# CTRL_MMR0_CFG0 register map
Vendor: Texas Instruments
Registers are 32-bit, read-write, reset 0x0 unless marked. A register's access mark holds for its fields unless they carry their own. Offsets are as the file gives them; [hi:lo] are bit positions; {n}, {i} and the like mark numbered series.

## CTRL_MMR0_CFG0 (part 9 of 10)
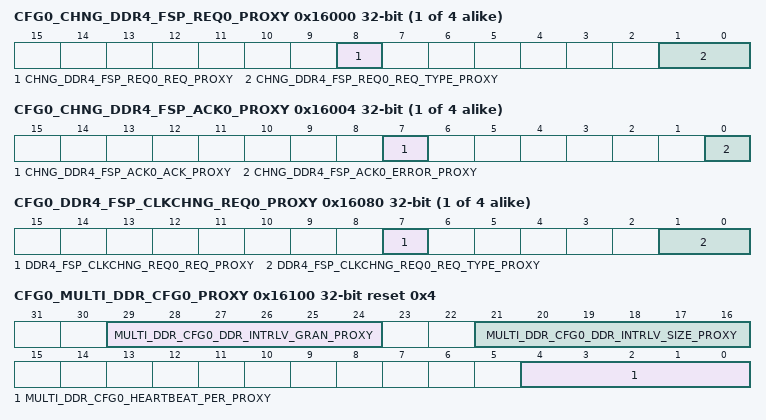
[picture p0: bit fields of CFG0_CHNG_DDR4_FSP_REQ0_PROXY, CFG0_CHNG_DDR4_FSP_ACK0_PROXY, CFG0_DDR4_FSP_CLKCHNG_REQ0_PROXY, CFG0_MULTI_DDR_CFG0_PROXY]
{0x16000+0x10*i} CFG0_CHNG_DDR4_FSP_REQ{i}_PROXY (i=0..3) — This register is used to initiate a LPDDR4 frequency set point change to the DDR {i} Controller
  [8] CHNG_DDR4_FSP_REQ{i}_REQ_PROXY — Initiate FSP frequency change
  [1:0] CHNG_DDR4_FSP_REQ{i}_REQ_TYPE_PROXY — Frequency request typeIndicates which DDR4 frequency set point to change to
{0x16004+0x10*i} CFG0_CHNG_DDR4_FSP_ACK{i}_PROXY ro (i=0..3) — This register is used by the DDR {i} Controller to acknowledge the LPDDR4 frequency set point change request
  [7] CHNG_DDR4_FSP_ACK{i}_ACK_PROXY — Frequency change acknowledge.This bit is only valid when CHNG_DDR4_FSP_REQ_req = 1Indication from the DDR Controller that the FSP change operation is complete 0 - FSP change operation in progress 1 - FSP change operation complete
  [0] CHNG_DDR4_FSP_ACK{i}_ERROR_PROXY — Frequency change errorThis bit is only valid when CHNG_DDR4_FSP_REQ_req = 1 0 - FSP change was successful 1 - FSP change was not successful
{0x16080+0x10*i} CFG0_DDR4_FSP_CLKCHNG_REQ{i}_PROXY ro (i=0..3) — This register is used by the DDR {i} Controller to request the DDR{i} PLL clock frequency change. This can occur as part of DDR4 initialization and training or in response to a LPDDR4 FSP change request.
  [7] DDR4_FSP_CLKCHNG_REQ{i}_REQ_PROXY — DDR Controller FSP clock change requestIndicates that the DDR controller needs the DDR clock changed to the frequency indicated by the req_type field. This bit is cleared when the DDR4_FSP_CLKCHNG_ACK_ack bit is set.
  [1:0] DDR4_FSP_CLKCHNG_REQ{i}_REQ_TYPE_PROXY — Frequency request typeIndicates which DDR4 FSP frequency to which the DDR Controller wants the DDR clock set
{0x160C0+0x10*i} CFG0_DDR4_FSP_CLKCHNG_ACK{i}_PROXY (i=0..3) — This register is used to acknowledge a DDR{i} PLL clock frequency change to the DDR{i} Controller.
  [0] DDR4_FSP_CLKCHNG_ACK{i}_ACK_PROXY — DDR FSP clock change acknowledgeThis bit should be set once the DDR clock has been successfully changed to the value requested by DDR4_FSP_CLKCHNG_REQ_req_type. Setting this bit will clear the DDR4_FSP_CLKCHNG_REQ_req bit and the associated change request interrupt.
0x16100 CFG0_MULTI_DDR_CFG0_PROXY reset 0x4 — Configures DDR interleaving
  [29:24] MULTI_DDR_CFG0_DDR_INTRLV_GRAN_PROXY — Defines the size of each memory stripe for interleaved memory space. Value takes effect when MULTI_DDR_CFG1_ddr_cfg _load field is set as 4'b0110. Field values (Others are reserved): 6'b000000 - 128 B 6'b000001 - 512 B 6'b000010 - 2 KB 6'b000011 - 4 KB 6'b000100 - 16 KB 6'b000101 - 32 KB 6'b000110 - 512 MB 6'b000111 - 1 GB 6'b001000 - 1.5 GB 6'b001001 - 2 GB 6'b001010 - 3 GB 6'b001011 - 4 GB 6'b001100 - 6 GB 6'b001101 - 8 GB 6'b001110 - 16 GB
  [21:16] MULTI_DDR_CFG0_DDR_INTRLV_SIZE_PROXY — Defines the memory window size for the interleaved region starting at the bottom of the external memory address range. Value takes effect when MULTI_DDR_CFG1_ddr_cfg _load field is set as 4'b0110. Field values (Others are reserved): 6'b000000 - 0 (no interleave) 6'b000001 - 128 MB 6'b000010 - 256 MB 6'b000011 - 512 MB 6'b000100 - 1 GB 6'b000101 - 2 GB 6'b000110 - 3 GB 6'b000111 - 4 GB 6'b001000 - 6 GB 6'b001001 - 8 GB 6'b001010 - 12 GB 6'b001011 - 16 GB 6'b001100 - 32 GB
  [4:0] MULTI_DDR_CFG0_HEARTBEAT_PER_PROXY — Determines number of cycles of unsuccessful EMIF arbitration to wait before arbitrating for a different EMIF port. Value takes effect when MULTI_DDR_CFG1_ddr_cfg _load field is set as 4'b0110. 0 - Heartbeat is disabled 1-31 - Number of cycles before port switch
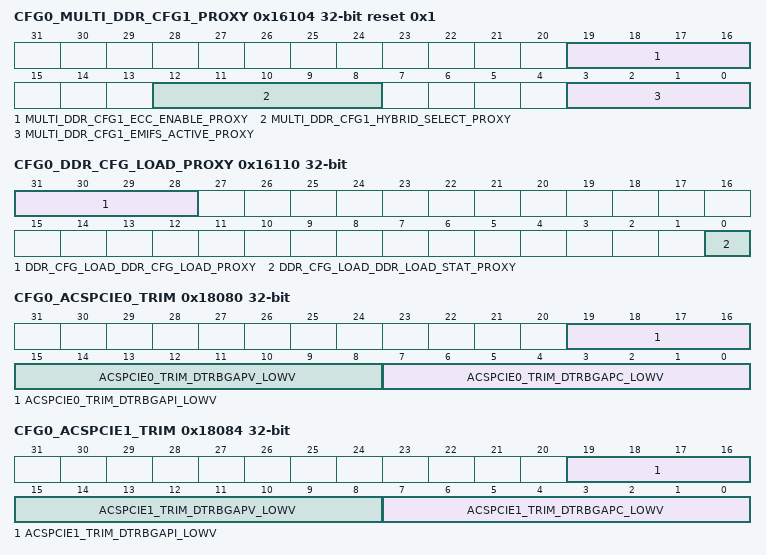
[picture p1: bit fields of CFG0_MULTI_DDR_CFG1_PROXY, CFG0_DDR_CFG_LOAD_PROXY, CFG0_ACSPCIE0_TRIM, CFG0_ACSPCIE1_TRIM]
0x16104 CFG0_MULTI_DDR_CFG1_PROXY reset 0x1 — Configures DDR interleaving
  [19:16] MULTI_DDR_CFG1_ECC_ENABLE_PROXY — Determines which EMIFs have ECC enabled. Value takes effect when MULTI_DDR_CFG1_ddr_cfg _load field is set as 4'b0110. Field values (Others are reserved): 4'b0000 - ECC disabled on all EMIFs 4'b0001 - ECC enabled on EMIF 0 4'b0010 - ECC enabled on EMIF 1 4'b0011 - ECC enabled on EMIF 0,1 4'b0100 - ECC enabled on EMIF 2 4'b0101 - ECC enabled on EMIF 0,2 4'b0110 - ECC enabled on EMIF 1,2 4'b0111 - ECC enabled on EMIF 0,1,2 4'b1000 - ECC enabled on EMIF 3 4'b1001 - ECC enabled on EMIF 0,3 4'b1010 - ECC enabled on EMIF 1,3 4'b1011 - ECC enabled on EMIF 0,1,3 4'b1100 - ECC enabled on EMIF 2,3 4'b1101 - ECC enabled on EMIF 0,2,3 4'b1110 - ECC enabled on EMIF 1,2,3 4'b1111 - ECC enabled on EMIF 0,1,2,3
  [12:8] MULTI_DDR_CFG1_HYBRID_SELECT_PROXY — Determines interleaved EMIF space location. Usage is based on number of EMIFs present. Value takes effect when MULTI_DDR_CFG1_ddr_cfg _load field is set as 4'b0110. Field values (Others are reserved): 4'b00000 - Entire EMIF space is interleaved 4'b00001 - 2 EMIFs - EMIF 0 separated, EMIF 0,1 interleaved 4'b00001 - 3 EMIFs - EMIF 0 separated, EMIF 1,2 interleaved 4'b00001 - 4 EMIFs - EMIF 0 separated, EMIF 1,2,3 interleaved 4'b00010 - 2 EMIFs - EMIF 1 separated, EMIF 0,1 interleaved 4'b00010 - 3 EMIFs - EMIF 1 separated, EMIF 0,2 interleaved 4'b00010 - 4 EMIFs - EMIF 1 separated, EMIF 0,2,3 interleaved 4'b00100 - 2 EMIFS - reserved 4'b00100 - 3 EMIFs - EMIF 2 separated, EMIF 0,1 interleaved 4'b00100 - 4 EMIFs - EMIF 2 separated, EMIF 0,1,3 interleaved 4'b01000 - 2 EMIFS - reserved 4'b01000 - 3 EMIFS - reserved 4'b01000 - 4 EMIFs - EMIF 3 separated, EMIF 0,1,2 interleaved 4'b10000 - reserved 4'b10001 - 2 EMIFs - EMIF 0 separated, EMIF 0,1 interleaved 4'b10001 - 3 EMIFs - EMIF 0 separated, EMIF 0,1,2 interleaved 4'b10001 - 4 EMIFs - EMIF 0 separated, EMIF 0,1,2,3 interleaved 4'b10010 - 2 EMIFs - EMIF 1 separated, EMIF 0,1 interleaved 4'b10010 - 3 EMIFs - EMIF 1 separated, EMIF 0,1,2 interleaved 4'b10010 - 4 EMIFs - EMIF 1 separated, EMIF 0,1,2,3 interleaved 4'b10100 - 2 EMIFS - reserved 4'b10100 - 3 EMIFs - EMIF 2 separated, EMIF 0,1,2 interleaved 4'b10100 - 4 EMIFS - EMIF 2 separated, EMIF 0,1,2,3 interleaved 4'b11000 - 2 EMIFS - reserved 4'b11000 - 3 EMIFS - reserved 4'b11000 - 4 EMIFs - EMIF 3 separated, EMIF 0,1,2,3 interleaved
  [3:0] MULTI_DDR_CFG1_EMIFS_ACTIVE_PROXY — Indicates which EMIF (DDR) interfaces are active. Value takes effect when MULTI_DDR_CFG1_ddr_cfg _load field is set as 4'b0110. Field values (Others are reserved): 4'b0000 - Reserved 4'b0001 - EMIF 0 Active 4'b0010 - EMIF 1 Active 4'b0011 - EMIF 0,1 Active 4'b0100 - EMIF 2 Active 4'b0101 - EMIF 0,2 Active 4'b0110 - EMIF 1,2 Active 4'b0111 - EMIF 0,1,2 Active 4'b1000 - EMIF 3 Active 4'b1001 - EMIF 0,3 Active 4'b1010 - EMIF 1,3 Active 4'b1011 - EMIF 0,1,3 Active 4'b1100 - EMIF 2,3 Active 4'b1101 - EMIF 0,2,3 Active 4'b1110 - EMIF 1,2,3 Active 4'b1111 - EMIF 0,1,2,3 Active
0x16110 CFG0_DDR_CFG_LOAD_PROXY access per field — Implements Multi-DDR configuration load and load status
  [31:28] DDR_CFG_LOAD_DDR_CFG_LOAD_PROXY rw — When set to 4'b0110, latches the ddr configuration bits into ComputeCluster. Once latched, the ComputeCluster ignores further transitions on its latch input so any further changes to this field have no effect.
  [0] DDR_CFG_LOAD_DDR_LOAD_STAT_PROXY ro — DDR configuration lock status bit indicating that DDR config load is complete
0x17008 CFG0_LOCK5_KICK0_PROXY — This register must be written with the designated key value followed by a write to LOCK5_KICK1 with its key value before write-protected Partition 5 registers can be written.
  [31:0] LOCK5_KICK0_PROXY — - KICK0 component
0x1700C CFG0_LOCK5_KICK1_PROXY — This register must be written with the designated key value after a write to LOCK5_KICK0 with its key value before write-protected Partition 5 registers can be written.
  [31:0] LOCK5_KICK1_PROXY — - KICK1 component
{0x17100+4i} CFG0_CLAIMREG_P5_R{i} (i=0..2)
  [31:0] CLAIMREG_P5_R{i} — Claim bits for Partition 5
0x18080 CFG0_ACSPCIE0_TRIM — Trims the ACSPCIE0 module Bandgap Regulator
  [19:16] ACSPCIE0_TRIM_DTRBGAPI_LOWV — Bandgap output current trim bits
  [15:8] ACSPCIE0_TRIM_DTRBGAPV_LOWV — Bandgap output voltage magnitude trim bits
  [7:0] ACSPCIE0_TRIM_DTRBGAPC_LOWV — Bandgap slope trim bits. Bit7 is used to calculate the offset
0x18084 CFG0_ACSPCIE1_TRIM — Trims the ACSPCIE1 module Bandgap Regulator
  [19:16] ACSPCIE1_TRIM_DTRBGAPI_LOWV — Bandgap output current trim bits
  [15:8] ACSPCIE1_TRIM_DTRBGAPV_LOWV — Bandgap output voltage magnitude trim bits
  [7:0] ACSPCIE1_TRIM_DTRBGAPC_LOWV — Bandgap slope trim bits. Bit7 is used to calculate the offset
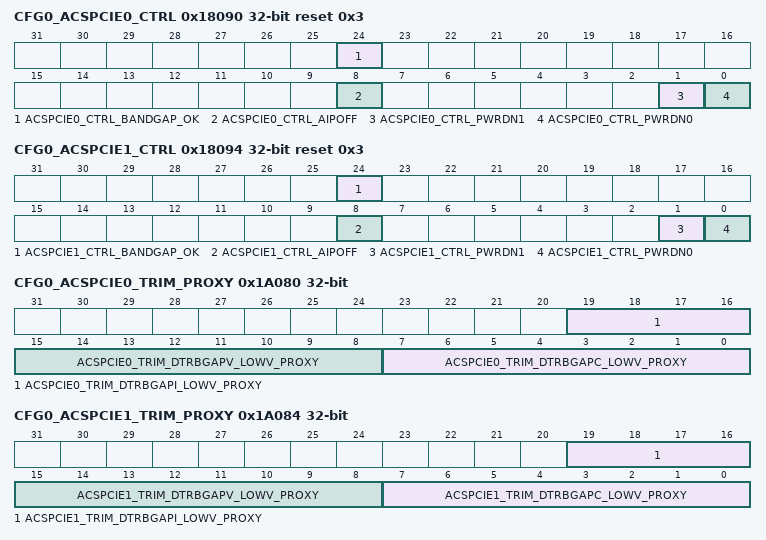
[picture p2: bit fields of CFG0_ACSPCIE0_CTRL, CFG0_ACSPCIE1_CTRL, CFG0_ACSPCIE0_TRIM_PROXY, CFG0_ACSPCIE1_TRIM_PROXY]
0x18090 CFG0_ACSPCIE0_CTRL access per field reset 0x3 — Controls the ACSPCIE0 module
  [24] ACSPCIE0_CTRL_BANDGAP_OK ro — Bandgap output okay
  [8] ACSPCIE0_CTRL_AIPOFF rw — Testmode enable
  [1] ACSPCIE0_CTRL_PWRDN1 rw — Disable (tristate) PAD1 IO buffers
  [0] ACSPCIE0_CTRL_PWRDN0 rw — Disable (tristate) PAD0 IO buffers
0x18094 CFG0_ACSPCIE1_CTRL access per field reset 0x3 — Controls the ACSPCIE1 module
  [24] ACSPCIE1_CTRL_BANDGAP_OK ro — Bandgap output okay
  [8] ACSPCIE1_CTRL_AIPOFF rw — Testmode enable
  [1] ACSPCIE1_CTRL_PWRDN1 rw — Disable (tristate) PAD1 IO buffers
  [0] ACSPCIE1_CTRL_PWRDN0 rw — Disable (tristate) PAD0 IO buffers
0x19100 CFG0_CLAIMREG_P6_R0_READONLY ro
  [31:0] CLAIMREG_P6_R0_READONLY — Claim bits for Partition 6
0x19104 CFG0_CLAIMREG_P6_R1_READONLY ro
  [31:0] CLAIMREG_P6_R1_READONLY — Claim bits for Partition 6
0x1A080 CFG0_ACSPCIE0_TRIM_PROXY — Trims the ACSPCIE0 module Bandgap Regulator
  [19:16] ACSPCIE0_TRIM_DTRBGAPI_LOWV_PROXY — Bandgap output current trim bits
  [15:8] ACSPCIE0_TRIM_DTRBGAPV_LOWV_PROXY — Bandgap output voltage magnitude trim bits
  [7:0] ACSPCIE0_TRIM_DTRBGAPC_LOWV_PROXY — Bandgap slope trim bits. Bit7 is used to calculate the offset
0x1A084 CFG0_ACSPCIE1_TRIM_PROXY — Trims the ACSPCIE1 module Bandgap Regulator
  [19:16] ACSPCIE1_TRIM_DTRBGAPI_LOWV_PROXY — Bandgap output current trim bits
  [15:8] ACSPCIE1_TRIM_DTRBGAPV_LOWV_PROXY — Bandgap output voltage magnitude trim bits
  [7:0] ACSPCIE1_TRIM_DTRBGAPC_LOWV_PROXY — Bandgap slope trim bits. Bit7 is used to calculate the offset
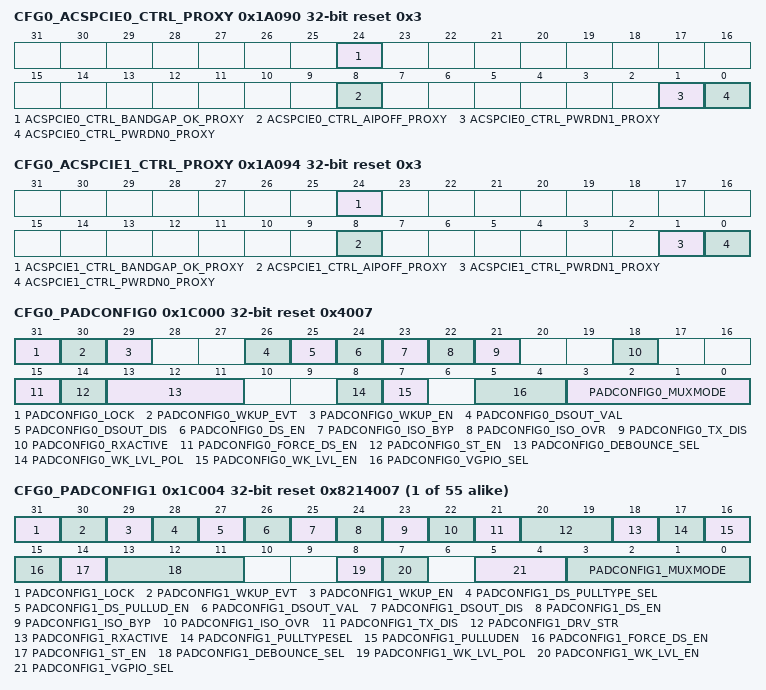
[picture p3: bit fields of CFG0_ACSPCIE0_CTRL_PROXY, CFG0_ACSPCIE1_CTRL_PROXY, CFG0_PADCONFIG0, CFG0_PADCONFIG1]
0x1A090 CFG0_ACSPCIE0_CTRL_PROXY access per field reset 0x3 — Controls the ACSPCIE0 module
  [24] ACSPCIE0_CTRL_BANDGAP_OK_PROXY ro — Bandgap output okay
  [8] ACSPCIE0_CTRL_AIPOFF_PROXY rw — Testmode enable
  [1] ACSPCIE0_CTRL_PWRDN1_PROXY rw — Disable (tristate) PAD1 IO buffers
  [0] ACSPCIE0_CTRL_PWRDN0_PROXY rw — Disable (tristate) PAD0 IO buffers
0x1A094 CFG0_ACSPCIE1_CTRL_PROXY access per field reset 0x3 — Controls the ACSPCIE1 module
  [24] ACSPCIE1_CTRL_BANDGAP_OK_PROXY ro — Bandgap output okay
  [8] ACSPCIE1_CTRL_AIPOFF_PROXY rw — Testmode enable
  [1] ACSPCIE1_CTRL_PWRDN1_PROXY rw — Disable (tristate) PAD1 IO buffers
  [0] ACSPCIE1_CTRL_PWRDN0_PROXY rw — Disable (tristate) PAD0 IO buffers
0x1B100 CFG0_CLAIMREG_P6_R0
  [31:0] CLAIMREG_P6_R0 — Claim bits for Partition 6
0x1B104 CFG0_CLAIMREG_P6_R1
  [31:0] CLAIMREG_P6_R1 — Claim bits for Partition 6
0x1C000 CFG0_PADCONFIG0 access per field reset 0x4007 — Register to control pin configuration and muxing
  [31] PADCONFIG0_LOCK rw — Lock 0 - Padconfig register is unlocked 1 - Padconfig register is locked from further writes
  [30] PADCONFIG0_WKUP_EVT ro — Wakeup event status 0 - No wake event on pin 1 - Wake event occurred on pin
  [29] PADCONFIG0_WKUP_EN rw — Wakeup enable 0 - Wakeup operation disabled 1 - Wakeup operation enabled
  [26] PADCONFIG0_DSOUT_VAL rw — Deep Sleep output value 0 - Output value is 0 1 - Output value is 1
  [25] PADCONFIG0_DSOUT_DIS rw — Deep Sleep output disable 0 - Output enabled 1 - Output disabled
  [24] PADCONFIG0_DS_EN rw — Deep Sleep override control 0 - IO keeps its previous state when Deep Sleep mode is active 1 - IO state is forced to OFF mode value when Deep Sleep mode is active
  [23] PADCONFIG0_ISO_BYP rw — Isolation Bypass0 - IO isolation is preserved1 - IO isolation is bypassed
  [22] PADCONFIG0_ISO_OVR rw — Isolation Override0 - IO isolation is preserved1 - IO isolation is overridden
  [21] PADCONFIG0_TX_DIS rw — Driver Disable0 - Driver is enabled1 - Driver is disabled
  [18] PADCONFIG0_RXACTIVE rw — Input enable for the Pad0 - Receiver disabled1 - Receiver enabled
  [15] PADCONFIG0_FORCE_DS_EN rw — Enable pad Deep Sleep controls by overriding DMSC gating0 - Deep Sleep pad controls are gated by the DMSC1 - Activate Deep Sleep pad controls (override DMSC gating logic)
  [14] PADCONFIG0_ST_EN rw — Receiver Schmitt Trigger enable 0 - Schmitt trigger input disabled 1 - Schmitt trigger input enabled
  [13:11] PADCONFIG0_DEBOUNCE_SEL rw — Selects the debouce period for the pad.
  [8] PADCONFIG0_WK_LVL_POL rw — Level Sensitive Wakeup PolarityThis bit is not relevant unless wk_lvl_en is set to 1'b1.0 - Low. A low (0) value on the pin causes a wakeup1 - High. A high (1) value on the pin causes a wakeup
  [7] PADCONFIG0_WK_LVL_EN rw — Level Sensitive Wakeup Enable0 - Disabled. Wakeup is triggered by change of the pin input value1 - Enabled. Wakeup is triggered when the pin matches the value specified by wk_lvl_pol. The chosen polarity must be maintained. (e.g. until wakeup completion is confirmed)
  [5:4] PADCONFIG0_VGPIO_SEL rw — Virtual MAIN_GPIO instance select.These bits select which instance of GPIO is used for this I/O pad. This allows protection between two different Processor virtual worlds. These bits have no effect if GPIO mode (muxmode=7) is not selected for the PAD. Field values (Others are reserved): 2'b00 - Implement GPIO in GPIO_WKUP_0 instance 2'b01 - Implement GPIO in GPIO_WKUP_2 instance 2'b10 - Implement GPIO in GPIO_WKUP_4 instance 2'b11 - Implement GPIO in GPIO_WKUP_6 instance
  [3:0] PADCONFIG0_MUXMODE rw — Pad functional signal mux selection Field values (Others are reserved): 4'b0000 - Mux Mode 0 4'b0001 - Mux Mode 1 4'b0010 - Mux Mode 2 4'b0011 - Mux Mode 3 4'b0100 - Mux Mode 4 4'b0101 - Mux Mode 5 4'b0110 - Mux Mode 6 4'b0111 - Mux Mode 7 4'b1000 - Mux Mode 8 4'b1001 - Mux Mode 9 4'b1010 - Mux Mode 10 4'b1011 - Mux Mode 11 4'b1100 - Mux Mode 12 4'b1101 - Mux Mode 13 4'b1110 - Mux Mode 14 4'b1111 - Mux Mode 15
{0x1C000+4i} CFG0_PADCONFIG{i} access per field reset 0x8214007 (i=1..55) — Register to control pin configuration and muxing
  [31] PADCONFIG{i}_LOCK rw — Lock 0 - Padconfig register is unlocked 1 - Padconfig register is locked from further writes
  [30] PADCONFIG{i}_WKUP_EVT ro — Wakeup event status 0 - No wake event on pin 1 - Wake event occurred on pin
  [29] PADCONFIG{i}_WKUP_EN rw — Wakeup enable 0 - Wakeup operation disabled 1 - Wakeup operation enabled
  [28] PADCONFIG{i}_DS_PULLTYPE_SEL rw — Deep Sleep pull-up/down selection 0 - Offmode pulldown selected 1 - Offmode pullup selected
  [27] PADCONFIG{i}_DS_PULLUD_EN rw — Deep Sleep pull-up/down enable (active low) 0 - Pullup / pulldown is enabled 1 - Pullup / pulldown is disabled
  [26] PADCONFIG{i}_DSOUT_VAL rw — Deep Sleep output value 0 - Output value is 0 1 - Output value is 1
  [25] PADCONFIG{i}_DSOUT_DIS rw — Deep Sleep output disable 0 - Output enabled 1 - Output disabled
  [24] PADCONFIG{i}_DS_EN rw — Deep Sleep override control 0 - IO keeps its previous state when Deep Sleep mode is active 1 - IO state is forced to OFF mode value when Deep Sleep mode is active
  [23] PADCONFIG{i}_ISO_BYP rw — Isolation Bypass0 - IO isolation is preserved1 - IO isolation is bypassed
  [22] PADCONFIG{i}_ISO_OVR rw — Isolation Override0 - IO isolation is preserved1 - IO isolation is overridden
  [21] PADCONFIG{i}_TX_DIS rw — Driver Disable0 - Driver is enabled1 - Driver is disabled
  [20:19] PADCONFIG{i}_DRV_STR rw — Drive Strength Control . Selects the drive strength value for LVCMOS pins. (Does not apply to other pin types)
  [18] PADCONFIG{i}_RXACTIVE rw — Input enable for the Pad0 - Receiver disabled1 - Receiver enabled
  [17] PADCONFIG{i}_PULLTYPESEL rw — Pad Pullup / Pulldown type selection0 - Pulldown selected1 - Pullup selected
  [16] PADCONFIG{i}_PULLUDEN rw — Pad Pullup / Pulldown enable. This is an active low signal.0 - Pullup / Pulldown enabled1 - Pullup / Pulldown disabled
  [15] PADCONFIG{i}_FORCE_DS_EN rw — Enable pad Deep Sleep controls by overriding DMSC gating0 - Deep Sleep pad controls are gated by the DMSC1 - Activate Deep Sleep pad controls (override DMSC gating logic)
  [14] PADCONFIG{i}_ST_EN rw — Receiver Schmitt Trigger enable 0 - Schmitt trigger input disabled 1 - Schmitt trigger input enabled
  [13:11] PADCONFIG{i}_DEBOUNCE_SEL rw — Selects the debouce period for the pad.
  [8] PADCONFIG{i}_WK_LVL_POL rw — Level Sensitive Wakeup PolarityThis bit is not relevant unless wk_lvl_en is set to 1'b1.0 - Low. A low (0) value on the pin causes a wakeup1 - High. A high (1) value on the pin causes a wakeup
  [7] PADCONFIG{i}_WK_LVL_EN rw — Level Sensitive Wakeup Enable0 - Disabled. Wakeup is triggered by change of the pin input value1 - Enabled. Wakeup is triggered when the pin matches the value specified by wk_lvl_pol. The chosen polarity must be maintained. (e.g. until wakeup completion is confirmed)
  [5:4] PADCONFIG{i}_VGPIO_SEL rw — Virtual MAIN_GPIO instance select.These bits select which instance of GPIO is used for this I/O pad. This allows protection between two different Processor virtual worlds. These bits have no effect if GPIO mode (muxmode=7) is not selected for the PAD. Field values (Others are reserved): 2'b00 - Implement GPIO in GPIO_WKUP_0 instance 2'b01 - Implement GPIO in GPIO_WKUP_2 instance 2'b10 - Implement GPIO in GPIO_WKUP_4 instance 2'b11 - Implement GPIO in GPIO_WKUP_6 instance
  [3:0] PADCONFIG{i}_MUXMODE rw — Pad functional signal mux selection Field values (Others are reserved): 4'b0000 - Mux Mode 0 4'b0001 - Mux Mode 1 4'b0010 - Mux Mode 2 4'b0011 - Mux Mode 3 4'b0100 - Mux Mode 4 4'b0101 - Mux Mode 5 4'b0110 - Mux Mode 6 4'b0111 - Mux Mode 7 4'b1000 - Mux Mode 8 4'b1001 - Mux Mode 9 4'b1010 - Mux Mode 10 4'b1011 - Mux Mode 11 4'b1100 - Mux Mode 12 4'b1101 - Mux Mode 13 4'b1110 - Mux Mode 14 4'b1111 - Mux Mode 15
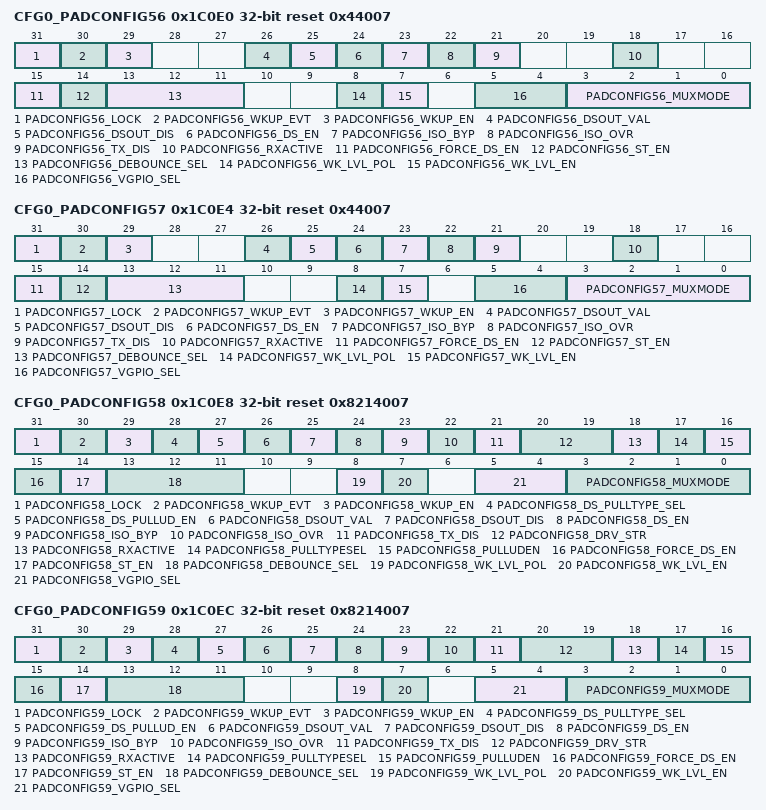
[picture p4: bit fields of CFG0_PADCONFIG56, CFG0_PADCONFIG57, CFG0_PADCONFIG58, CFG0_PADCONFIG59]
0x1C0E0 CFG0_PADCONFIG56 access per field reset 0x44007 — Register to control pin configuration and muxing
  [31] PADCONFIG56_LOCK rw — Lock 0 - Padconfig register is unlocked 1 - Padconfig register is locked from further writes
  [30] PADCONFIG56_WKUP_EVT ro — Wakeup event status 0 - No wake event on pin 1 - Wake event occurred on pin
  [29] PADCONFIG56_WKUP_EN rw — Wakeup enable 0 - Wakeup operation disabled 1 - Wakeup operation enabled
  [26] PADCONFIG56_DSOUT_VAL rw — Deep Sleep output value 0 - Output value is 0 1 - Output value is 1
  [25] PADCONFIG56_DSOUT_DIS rw — Deep Sleep output disable 0 - Output enabled 1 - Output disabled
  [24] PADCONFIG56_DS_EN rw — Deep Sleep override control 0 - IO keeps its previous state when Deep Sleep mode is active 1 - IO state is forced to OFF mode value when Deep Sleep mode is active
  [23] PADCONFIG56_ISO_BYP rw — Isolation Bypass0 - IO isolation is preserved1 - IO isolation is bypassed
  [22] PADCONFIG56_ISO_OVR rw — Isolation Override0 - IO isolation is preserved1 - IO isolation is overridden
  [21] PADCONFIG56_TX_DIS rw — Driver Disable0 - Driver is enabled1 - Driver is disabled
  [18] PADCONFIG56_RXACTIVE rw — Input enable for the Pad0 - Receiver disabled1 - Receiver enabled
  [15] PADCONFIG56_FORCE_DS_EN rw — Enable pad Deep Sleep controls by overriding DMSC gating0 - Deep Sleep pad controls are gated by the DMSC1 - Activate Deep Sleep pad controls (override DMSC gating logic)
  [14] PADCONFIG56_ST_EN rw — Receiver Schmitt Trigger enable 0 - Schmitt trigger input disabled 1 - Schmitt trigger input enabled
  [13:11] PADCONFIG56_DEBOUNCE_SEL rw — Selects the debouce period for the pad.
  [8] PADCONFIG56_WK_LVL_POL rw — Level Sensitive Wakeup PolarityThis bit is not relevant unless wk_lvl_en is set to 1'b1.0 - Low. A low (0) value on the pin causes a wakeup1 - High. A high (1) value on the pin causes a wakeup
  [7] PADCONFIG56_WK_LVL_EN rw — Level Sensitive Wakeup Enable0 - Disabled. Wakeup is triggered by change of the pin input value1 - Enabled. Wakeup is triggered when the pin matches the value specified by wk_lvl_pol. The chosen polarity must be maintained. (e.g. until wakeup completion is confirmed)
  [5:4] PADCONFIG56_VGPIO_SEL rw — Virtual MAIN_GPIO instance select.These bits select which instance of GPIO is used for this I/O pad. This allows protection between two different Processor virtual worlds. These bits have no effect if GPIO mode (muxmode=7) is not selected for the PAD. Field values (Others are reserved): 2'b00 - Implement GPIO in GPIO_WKUP_0 instance 2'b01 - Implement GPIO in GPIO_WKUP_2 instance 2'b10 - Implement GPIO in GPIO_WKUP_4 instance 2'b11 - Implement GPIO in GPIO_WKUP_6 instance
  [3:0] PADCONFIG56_MUXMODE rw — Pad functional signal mux selection Field values (Others are reserved): 4'b0000 - Mux Mode 0 4'b0001 - Mux Mode 1 4'b0010 - Mux Mode 2 4'b0011 - Mux Mode 3 4'b0100 - Mux Mode 4 4'b0101 - Mux Mode 5 4'b0110 - Mux Mode 6 4'b0111 - Mux Mode 7 4'b1000 - Mux Mode 8 4'b1001 - Mux Mode 9 4'b1010 - Mux Mode 10 4'b1011 - Mux Mode 11 4'b1100 - Mux Mode 12 4'b1101 - Mux Mode 13 4'b1110 - Mux Mode 14 4'b1111 - Mux Mode 15
0x1C0E4 CFG0_PADCONFIG57 access per field reset 0x44007 — Register to control pin configuration and muxing
  [31] PADCONFIG57_LOCK rw — Lock 0 - Padconfig register is unlocked 1 - Padconfig register is locked from further writes
  [30] PADCONFIG57_WKUP_EVT ro — Wakeup event status 0 - No wake event on pin 1 - Wake event occurred on pin
  [29] PADCONFIG57_WKUP_EN rw — Wakeup enable 0 - Wakeup operation disabled 1 - Wakeup operation enabled
  [26] PADCONFIG57_DSOUT_VAL rw — Deep Sleep output value 0 - Output value is 0 1 - Output value is 1
  [25] PADCONFIG57_DSOUT_DIS rw — Deep Sleep output disable 0 - Output enabled 1 - Output disabled
  [24] PADCONFIG57_DS_EN rw — Deep Sleep override control 0 - IO keeps its previous state when Deep Sleep mode is active 1 - IO state is forced to OFF mode value when Deep Sleep mode is active
  [23] PADCONFIG57_ISO_BYP rw — Isolation Bypass0 - IO isolation is preserved1 - IO isolation is bypassed
  [22] PADCONFIG57_ISO_OVR rw — Isolation Override0 - IO isolation is preserved1 - IO isolation is overridden
  [21] PADCONFIG57_TX_DIS rw — Driver Disable0 - Driver is enabled1 - Driver is disabled
  [18] PADCONFIG57_RXACTIVE rw — Input enable for the Pad0 - Receiver disabled1 - Receiver enabled
  [15] PADCONFIG57_FORCE_DS_EN rw — Enable pad Deep Sleep controls by overriding DMSC gating0 - Deep Sleep pad controls are gated by the DMSC1 - Activate Deep Sleep pad controls (override DMSC gating logic)
  [14] PADCONFIG57_ST_EN rw — Receiver Schmitt Trigger enable 0 - Schmitt trigger input disabled 1 - Schmitt trigger input enabled
  [13:11] PADCONFIG57_DEBOUNCE_SEL rw — Selects the debouce period for the pad.
  [8] PADCONFIG57_WK_LVL_POL rw — Level Sensitive Wakeup PolarityThis bit is not relevant unless wk_lvl_en is set to 1'b1.0 - Low. A low (0) value on the pin causes a wakeup1 - High. A high (1) value on the pin causes a wakeup
  [7] PADCONFIG57_WK_LVL_EN rw — Level Sensitive Wakeup Enable0 - Disabled. Wakeup is triggered by change of the pin input value1 - Enabled. Wakeup is triggered when the pin matches the value specified by wk_lvl_pol. The chosen polarity must be maintained. (e.g. until wakeup completion is confirmed)
  [5:4] PADCONFIG57_VGPIO_SEL rw — Virtual MAIN_GPIO instance select.These bits select which instance of GPIO is used for this I/O pad. This allows protection between two different Processor virtual worlds. These bits have no effect if GPIO mode (muxmode=7) is not selected for the PAD. Field values (Others are reserved): 2'b00 - Implement GPIO in GPIO_WKUP_0 instance 2'b01 - Implement GPIO in GPIO_WKUP_2 instance 2'b10 - Implement GPIO in GPIO_WKUP_4 instance 2'b11 - Implement GPIO in GPIO_WKUP_6 instance
  [3:0] PADCONFIG57_MUXMODE rw — Pad functional signal mux selection Field values (Others are reserved): 4'b0000 - Mux Mode 0 4'b0001 - Mux Mode 1 4'b0010 - Mux Mode 2 4'b0011 - Mux Mode 3 4'b0100 - Mux Mode 4 4'b0101 - Mux Mode 5 4'b0110 - Mux Mode 6 4'b0111 - Mux Mode 7 4'b1000 - Mux Mode 8 4'b1001 - Mux Mode 9 4'b1010 - Mux Mode 10 4'b1011 - Mux Mode 11 4'b1100 - Mux Mode 12 4'b1101 - Mux Mode 13 4'b1110 - Mux Mode 14 4'b1111 - Mux Mode 15
0x1C0E8 CFG0_PADCONFIG58 access per field reset 0x8214007 — Register to control pin configuration and muxing
  [31] PADCONFIG58_LOCK rw — Lock 0 - Padconfig register is unlocked 1 - Padconfig register is locked from further writes
  [30] PADCONFIG58_WKUP_EVT ro — Wakeup event status 0 - No wake event on pin 1 - Wake event occurred on pin
  [29] PADCONFIG58_WKUP_EN rw — Wakeup enable 0 - Wakeup operation disabled 1 - Wakeup operation enabled
  [28] PADCONFIG58_DS_PULLTYPE_SEL rw — Deep Sleep pull-up/down selection 0 - Offmode pulldown selected 1 - Offmode pullup selected
  [27] PADCONFIG58_DS_PULLUD_EN rw — Deep Sleep pull-up/down enable (active low) 0 - Pullup / pulldown is enabled 1 - Pullup / pulldown is disabled
  [26] PADCONFIG58_DSOUT_VAL rw — Deep Sleep output value 0 - Output value is 0 1 - Output value is 1
  [25] PADCONFIG58_DSOUT_DIS rw — Deep Sleep output disable 0 - Output enabled 1 - Output disabled
  [24] PADCONFIG58_DS_EN rw — Deep Sleep override control 0 - IO keeps its previous state when Deep Sleep mode is active 1 - IO state is forced to OFF mode value when Deep Sleep mode is active
  [23] PADCONFIG58_ISO_BYP rw — Isolation Bypass0 - IO isolation is preserved1 - IO isolation is bypassed
  [22] PADCONFIG58_ISO_OVR rw — Isolation Override0 - IO isolation is preserved1 - IO isolation is overridden
  [21] PADCONFIG58_TX_DIS rw — Driver Disable0 - Driver is enabled1 - Driver is disabled
  [20:19] PADCONFIG58_DRV_STR rw — Drive Strength Control . Selects the drive strength value for LVCMOS pins. (Does not apply to other pin types)
  [18] PADCONFIG58_RXACTIVE rw — Input enable for the Pad0 - Receiver disabled1 - Receiver enabled
  [17] PADCONFIG58_PULLTYPESEL rw — Pad Pullup / Pulldown type selection0 - Pulldown selected1 - Pullup selected
  [16] PADCONFIG58_PULLUDEN rw — Pad Pullup / Pulldown enable. This is an active low signal.0 - Pullup / Pulldown enabled1 - Pullup / Pulldown disabled
  [15] PADCONFIG58_FORCE_DS_EN rw — Enable pad Deep Sleep controls by overriding DMSC gating0 - Deep Sleep pad controls are gated by the DMSC1 - Activate Deep Sleep pad controls (override DMSC gating logic)
  [14] PADCONFIG58_ST_EN rw — Receiver Schmitt Trigger enable 0 - Schmitt trigger input disabled 1 - Schmitt trigger input enabled
  [13:11] PADCONFIG58_DEBOUNCE_SEL rw — Selects the debouce period for the pad.
  [8] PADCONFIG58_WK_LVL_POL rw — Level Sensitive Wakeup PolarityThis bit is not relevant unless wk_lvl_en is set to 1'b1.0 - Low. A low (0) value on the pin causes a wakeup1 - High. A high (1) value on the pin causes a wakeup
  [7] PADCONFIG58_WK_LVL_EN rw — Level Sensitive Wakeup Enable0 - Disabled. Wakeup is triggered by change of the pin input value1 - Enabled. Wakeup is triggered when the pin matches the value specified by wk_lvl_pol. The chosen polarity must be maintained. (e.g. until wakeup completion is confirmed)
  [5:4] PADCONFIG58_VGPIO_SEL rw — Virtual MAIN_GPIO instance select.These bits select which instance of GPIO is used for this I/O pad. This allows protection between two different Processor virtual worlds. These bits have no effect if GPIO mode (muxmode=7) is not selected for the PAD. Field values (Others are reserved): 2'b00 - Implement GPIO in GPIO_WKUP_0 instance 2'b01 - Implement GPIO in GPIO_WKUP_2 instance 2'b10 - Implement GPIO in GPIO_WKUP_4 instance 2'b11 - Implement GPIO in GPIO_WKUP_6 instance
  [3:0] PADCONFIG58_MUXMODE rw — Pad functional signal mux selection Field values (Others are reserved): 4'b0000 - Mux Mode 0 4'b0001 - Mux Mode 1 4'b0010 - Mux Mode 2 4'b0011 - Mux Mode 3 4'b0100 - Mux Mode 4 4'b0101 - Mux Mode 5 4'b0110 - Mux Mode 6 4'b0111 - Mux Mode 7 4'b1000 - Mux Mode 8 4'b1001 - Mux Mode 9 4'b1010 - Mux Mode 10 4'b1011 - Mux Mode 11 4'b1100 - Mux Mode 12 4'b1101 - Mux Mode 13 4'b1110 - Mux Mode 14 4'b1111 - Mux Mode 15
0x1C0EC CFG0_PADCONFIG59 access per field reset 0x8214007 — Register to control pin configuration and muxing
  [31] PADCONFIG59_LOCK rw — Lock 0 - Padconfig register is unlocked 1 - Padconfig register is locked from further writes
  [30] PADCONFIG59_WKUP_EVT ro — Wakeup event status 0 - No wake event on pin 1 - Wake event occurred on pin
  [29] PADCONFIG59_WKUP_EN rw — Wakeup enable 0 - Wakeup operation disabled 1 - Wakeup operation enabled
  [28] PADCONFIG59_DS_PULLTYPE_SEL rw — Deep Sleep pull-up/down selection 0 - Offmode pulldown selected 1 - Offmode pullup selected
  [27] PADCONFIG59_DS_PULLUD_EN rw — Deep Sleep pull-up/down enable (active low) 0 - Pullup / pulldown is enabled 1 - Pullup / pulldown is disabled
  [26] PADCONFIG59_DSOUT_VAL rw — Deep Sleep output value 0 - Output value is 0 1 - Output value is 1
  [25] PADCONFIG59_DSOUT_DIS rw — Deep Sleep output disable 0 - Output enabled 1 - Output disabled
  [24] PADCONFIG59_DS_EN rw — Deep Sleep override control 0 - IO keeps its previous state when Deep Sleep mode is active 1 - IO state is forced to OFF mode value when Deep Sleep mode is active
  [23] PADCONFIG59_ISO_BYP rw — Isolation Bypass0 - IO isolation is preserved1 - IO isolation is bypassed
  [22] PADCONFIG59_ISO_OVR rw — Isolation Override0 - IO isolation is preserved1 - IO isolation is overridden
  [21] PADCONFIG59_TX_DIS rw — Driver Disable0 - Driver is enabled1 - Driver is disabled
  [20:19] PADCONFIG59_DRV_STR rw — Drive Strength Control . Selects the drive strength value for LVCMOS pins. (Does not apply to other pin types)
  [18] PADCONFIG59_RXACTIVE rw — Input enable for the Pad0 - Receiver disabled1 - Receiver enabled
  [17] PADCONFIG59_PULLTYPESEL rw — Pad Pullup / Pulldown type selection0 - Pulldown selected1 - Pullup selected
  [16] PADCONFIG59_PULLUDEN rw — Pad Pullup / Pulldown enable. This is an active low signal.0 - Pullup / Pulldown enabled1 - Pullup / Pulldown disabled
  [15] PADCONFIG59_FORCE_DS_EN rw — Enable pad Deep Sleep controls by overriding DMSC gating0 - Deep Sleep pad controls are gated by the DMSC1 - Activate Deep Sleep pad controls (override DMSC gating logic)
  [14] PADCONFIG59_ST_EN rw — Receiver Schmitt Trigger enable 0 - Schmitt trigger input disabled 1 - Schmitt trigger input enabled
  [13:11] PADCONFIG59_DEBOUNCE_SEL rw — Selects the debouce period for the pad.
  [8] PADCONFIG59_WK_LVL_POL rw — Level Sensitive Wakeup PolarityThis bit is not relevant unless wk_lvl_en is set to 1'b1.0 - Low. A low (0) value on the pin causes a wakeup1 - High. A high (1) value on the pin causes a wakeup
  [7] PADCONFIG59_WK_LVL_EN rw — Level Sensitive Wakeup Enable0 - Disabled. Wakeup is triggered by change of the pin input value1 - Enabled. Wakeup is triggered when the pin matches the value specified by wk_lvl_pol. The chosen polarity must be maintained. (e.g. until wakeup completion is confirmed)
  [5:4] PADCONFIG59_VGPIO_SEL rw — Virtual MAIN_GPIO instance select.These bits select which instance of GPIO is used for this I/O pad. This allows protection between two different Processor virtual worlds. These bits have no effect if GPIO mode (muxmode=7) is not selected for the PAD. Field values (Others are reserved): 2'b00 - Implement GPIO in GPIO_WKUP_0 instance 2'b01 - Implement GPIO in GPIO_WKUP_2 instance 2'b10 - Implement GPIO in GPIO_WKUP_4 instance 2'b11 - Implement GPIO in GPIO_WKUP_6 instance
  [3:0] PADCONFIG59_MUXMODE rw — Pad functional signal mux selection Field values (Others are reserved): 4'b0000 - Mux Mode 0 4'b0001 - Mux Mode 1 4'b0010 - Mux Mode 2 4'b0011 - Mux Mode 3 4'b0100 - Mux Mode 4 4'b0101 - Mux Mode 5 4'b0110 - Mux Mode 6 4'b0111 - Mux Mode 7 4'b1000 - Mux Mode 8 4'b1001 - Mux Mode 9 4'b1010 - Mux Mode 10 4'b1011 - Mux Mode 11 4'b1100 - Mux Mode 12 4'b1101 - Mux Mode 13 4'b1110 - Mux Mode 14 4'b1111 - Mux Mode 15
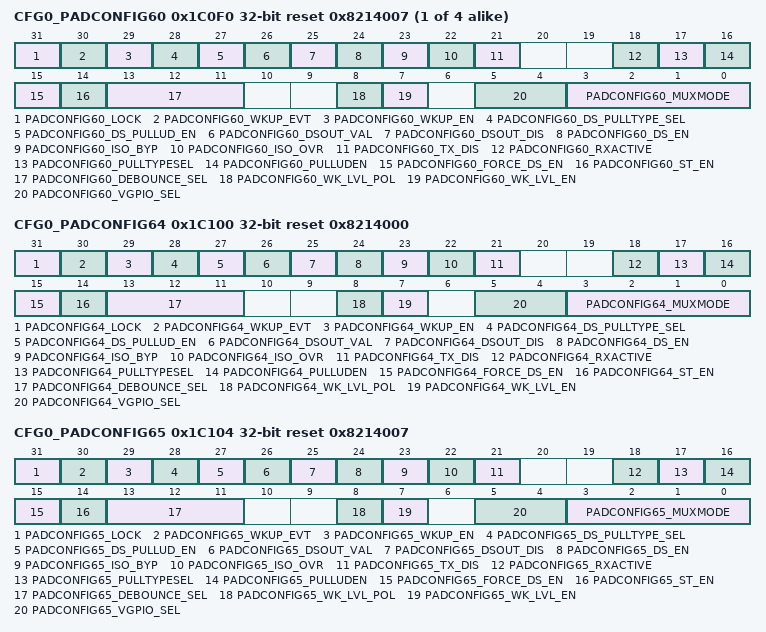
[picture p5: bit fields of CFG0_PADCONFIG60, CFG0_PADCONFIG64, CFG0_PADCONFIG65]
{0x1C000+4i} CFG0_PADCONFIG{i} access per field reset 0x8214007 (i=60..63) — Register to control pin configuration and muxing
  [31] PADCONFIG{i}_LOCK rw — Lock 0 - Padconfig register is unlocked 1 - Padconfig register is locked from further writes
  [30] PADCONFIG{i}_WKUP_EVT ro — Wakeup event status 0 - No wake event on pin 1 - Wake event occurred on pin
  [29] PADCONFIG{i}_WKUP_EN rw — Wakeup enable 0 - Wakeup operation disabled 1 - Wakeup operation enabled
  [28] PADCONFIG{i}_DS_PULLTYPE_SEL rw — Deep Sleep pull-up/down selection 0 - Offmode pulldown selected 1 - Offmode pullup selected
  [27] PADCONFIG{i}_DS_PULLUD_EN rw — Deep Sleep pull-up/down enable (active low) 0 - Pullup / pulldown is enabled 1 - Pullup / pulldown is disabled
  [26] PADCONFIG{i}_DSOUT_VAL rw — Deep Sleep output value 0 - Output value is 0 1 - Output value is 1
  [25] PADCONFIG{i}_DSOUT_DIS rw — Deep Sleep output disable 0 - Output enabled 1 - Output disabled
  [24] PADCONFIG{i}_DS_EN rw — Deep Sleep override control 0 - IO keeps its previous state when Deep Sleep mode is active 1 - IO state is forced to OFF mode value when Deep Sleep mode is active
  [23] PADCONFIG{i}_ISO_BYP rw — Isolation Bypass0 - IO isolation is preserved1 - IO isolation is bypassed
  [22] PADCONFIG{i}_ISO_OVR rw — Isolation Override0 - IO isolation is preserved1 - IO isolation is overridden
  [21] PADCONFIG{i}_TX_DIS rw — Driver Disable0 - Driver is enabled1 - Driver is disabled
  [18] PADCONFIG{i}_RXACTIVE rw — Input enable for the Pad0 - Receiver disabled1 - Receiver enabled
  [17] PADCONFIG{i}_PULLTYPESEL rw — Pad Pullup / Pulldown type selection0 - Pulldown selected1 - Pullup selected
  [16] PADCONFIG{i}_PULLUDEN rw — Pad Pullup / Pulldown enable. This is an active low signal.0 - Pullup / Pulldown enabled1 - Pullup / Pulldown disabled
  [15] PADCONFIG{i}_FORCE_DS_EN rw — Enable pad Deep Sleep controls by overriding DMSC gating0 - Deep Sleep pad controls are gated by the DMSC1 - Activate Deep Sleep pad controls (override DMSC gating logic)
  [14] PADCONFIG{i}_ST_EN rw — Receiver Schmitt Trigger enable 0 - Schmitt trigger input disabled 1 - Schmitt trigger input enabled
  [13:11] PADCONFIG{i}_DEBOUNCE_SEL rw — Selects the debouce period for the pad.
  [8] PADCONFIG{i}_WK_LVL_POL rw — Level Sensitive Wakeup PolarityThis bit is not relevant unless wk_lvl_en is set to 1'b1.0 - Low. A low (0) value on the pin causes a wakeup1 - High. A high (1) value on the pin causes a wakeup
  [7] PADCONFIG{i}_WK_LVL_EN rw — Level Sensitive Wakeup Enable0 - Disabled. Wakeup is triggered by change of the pin input value1 - Enabled. Wakeup is triggered when the pin matches the value specified by wk_lvl_pol. The chosen polarity must be maintained. (e.g. until wakeup completion is confirmed)
  [5:4] PADCONFIG{i}_VGPIO_SEL rw — Virtual MAIN_GPIO instance select.These bits select which instance of GPIO is used for this I/O pad. This allows protection between two different Processor virtual worlds. These bits have no effect if GPIO mode (muxmode=7) is not selected for the PAD. Field values (Others are reserved): 2'b00 - Implement GPIO in GPIO_WKUP_0 instance 2'b01 - Implement GPIO in GPIO_WKUP_2 instance 2'b10 - Implement GPIO in GPIO_WKUP_4 instance 2'b11 - Implement GPIO in GPIO_WKUP_6 instance
  [3:0] PADCONFIG{i}_MUXMODE rw — Pad functional signal mux selection Field values (Others are reserved): 4'b0000 - Mux Mode 0 4'b0001 - Mux Mode 1 4'b0010 - Mux Mode 2 4'b0011 - Mux Mode 3 4'b0100 - Mux Mode 4 4'b0101 - Mux Mode 5 4'b0110 - Mux Mode 6 4'b0111 - Mux Mode 7 4'b1000 - Mux Mode 8 4'b1001 - Mux Mode 9 4'b1010 - Mux Mode 10 4'b1011 - Mux Mode 11 4'b1100 - Mux Mode 12 4'b1101 - Mux Mode 13 4'b1110 - Mux Mode 14 4'b1111 - Mux Mode 15
0x1C100 CFG0_PADCONFIG64 access per field reset 0x8214000 — Register to control pin configuration and muxing
  [31] PADCONFIG64_LOCK rw — Lock 0 - Padconfig register is unlocked 1 - Padconfig register is locked from further writes
  [30] PADCONFIG64_WKUP_EVT ro — Wakeup event status 0 - No wake event on pin 1 - Wake event occurred on pin
  [29] PADCONFIG64_WKUP_EN rw — Wakeup enable 0 - Wakeup operation disabled 1 - Wakeup operation enabled
  [28] PADCONFIG64_DS_PULLTYPE_SEL rw — Deep Sleep pull-up/down selection 0 - Offmode pulldown selected 1 - Offmode pullup selected
  [27] PADCONFIG64_DS_PULLUD_EN rw — Deep Sleep pull-up/down enable (active low) 0 - Pullup / pulldown is enabled 1 - Pullup / pulldown is disabled
  [26] PADCONFIG64_DSOUT_VAL rw — Deep Sleep output value 0 - Output value is 0 1 - Output value is 1
  [25] PADCONFIG64_DSOUT_DIS rw — Deep Sleep output disable 0 - Output enabled 1 - Output disabled
  [24] PADCONFIG64_DS_EN rw — Deep Sleep override control 0 - IO keeps its previous state when Deep Sleep mode is active 1 - IO state is forced to OFF mode value when Deep Sleep mode is active
  [23] PADCONFIG64_ISO_BYP rw — Isolation Bypass0 - IO isolation is preserved1 - IO isolation is bypassed
  [22] PADCONFIG64_ISO_OVR rw — Isolation Override0 - IO isolation is preserved1 - IO isolation is overridden
  [21] PADCONFIG64_TX_DIS rw — Driver Disable0 - Driver is enabled1 - Driver is disabled
  [18] PADCONFIG64_RXACTIVE rw — Input enable for the Pad0 - Receiver disabled1 - Receiver enabled
  [17] PADCONFIG64_PULLTYPESEL rw — Pad Pullup / Pulldown type selection0 - Pulldown selected1 - Pullup selected
  [16] PADCONFIG64_PULLUDEN rw — Pad Pullup / Pulldown enable. This is an active low signal.0 - Pullup / Pulldown enabled1 - Pullup / Pulldown disabled
  [15] PADCONFIG64_FORCE_DS_EN rw — Enable pad Deep Sleep controls by overriding DMSC gating0 - Deep Sleep pad controls are gated by the DMSC1 - Activate Deep Sleep pad controls (override DMSC gating logic)
  [14] PADCONFIG64_ST_EN rw — Receiver Schmitt Trigger enable 0 - Schmitt trigger input disabled 1 - Schmitt trigger input enabled
  [13:11] PADCONFIG64_DEBOUNCE_SEL rw — Selects the debouce period for the pad.
  [8] PADCONFIG64_WK_LVL_POL rw — Level Sensitive Wakeup PolarityThis bit is not relevant unless wk_lvl_en is set to 1'b1.0 - Low. A low (0) value on the pin causes a wakeup1 - High. A high (1) value on the pin causes a wakeup
  [7] PADCONFIG64_WK_LVL_EN rw — Level Sensitive Wakeup Enable0 - Disabled. Wakeup is triggered by change of the pin input value1 - Enabled. Wakeup is triggered when the pin matches the value specified by wk_lvl_pol. The chosen polarity must be maintained. (e.g. until wakeup completion is confirmed)
  [5:4] PADCONFIG64_VGPIO_SEL rw — Virtual MAIN_GPIO instance select.These bits select which instance of GPIO is used for this I/O pad. This allows protection between two different Processor virtual worlds. These bits have no effect if GPIO mode (muxmode=7) is not selected for the PAD. Field values (Others are reserved): 2'b00 - Implement GPIO in GPIO_WKUP_0 instance 2'b01 - Implement GPIO in GPIO_WKUP_2 instance 2'b10 - Implement GPIO in GPIO_WKUP_4 instance 2'b11 - Implement GPIO in GPIO_WKUP_6 instance
  [3:0] PADCONFIG64_MUXMODE rw — Pad functional signal mux selection Field values (Others are reserved): 4'b0000 - Mux Mode 0 4'b0001 - Mux Mode 1 4'b0010 - Mux Mode 2 4'b0011 - Mux Mode 3 4'b0100 - Mux Mode 4 4'b0101 - Mux Mode 5 4'b0110 - Mux Mode 6 4'b0111 - Mux Mode 7 4'b1000 - Mux Mode 8 4'b1001 - Mux Mode 9 4'b1010 - Mux Mode 10 4'b1011 - Mux Mode 11 4'b1100 - Mux Mode 12 4'b1101 - Mux Mode 13 4'b1110 - Mux Mode 14 4'b1111 - Mux Mode 15
0x1C104 CFG0_PADCONFIG65 access per field reset 0x8214007 — Register to control pin configuration and muxing
  [31] PADCONFIG65_LOCK rw — Lock 0 - Padconfig register is unlocked 1 - Padconfig register is locked from further writes
  [30] PADCONFIG65_WKUP_EVT ro — Wakeup event status 0 - No wake event on pin 1 - Wake event occurred on pin
  [29] PADCONFIG65_WKUP_EN rw — Wakeup enable 0 - Wakeup operation disabled 1 - Wakeup operation enabled
  [28] PADCONFIG65_DS_PULLTYPE_SEL rw — Deep Sleep pull-up/down selection 0 - Offmode pulldown selected 1 - Offmode pullup selected
  [27] PADCONFIG65_DS_PULLUD_EN rw — Deep Sleep pull-up/down enable (active low) 0 - Pullup / pulldown is enabled 1 - Pullup / pulldown is disabled
  [26] PADCONFIG65_DSOUT_VAL rw — Deep Sleep output value 0 - Output value is 0 1 - Output value is 1
  [25] PADCONFIG65_DSOUT_DIS rw — Deep Sleep output disable 0 - Output enabled 1 - Output disabled
  [24] PADCONFIG65_DS_EN rw — Deep Sleep override control 0 - IO keeps its previous state when Deep Sleep mode is active 1 - IO state is forced to OFF mode value when Deep Sleep mode is active
  [23] PADCONFIG65_ISO_BYP rw — Isolation Bypass0 - IO isolation is preserved1 - IO isolation is bypassed
  [22] PADCONFIG65_ISO_OVR rw — Isolation Override0 - IO isolation is preserved1 - IO isolation is overridden
  [21] PADCONFIG65_TX_DIS rw — Driver Disable0 - Driver is enabled1 - Driver is disabled
  [18] PADCONFIG65_RXACTIVE rw — Input enable for the Pad0 - Receiver disabled1 - Receiver enabled
  [17] PADCONFIG65_PULLTYPESEL rw — Pad Pullup / Pulldown type selection0 - Pulldown selected1 - Pullup selected
  [16] PADCONFIG65_PULLUDEN rw — Pad Pullup / Pulldown enable. This is an active low signal.0 - Pullup / Pulldown enabled1 - Pullup / Pulldown disabled
  [15] PADCONFIG65_FORCE_DS_EN rw — Enable pad Deep Sleep controls by overriding DMSC gating0 - Deep Sleep pad controls are gated by the DMSC1 - Activate Deep Sleep pad controls (override DMSC gating logic)
  [14] PADCONFIG65_ST_EN rw — Receiver Schmitt Trigger enable 0 - Schmitt trigger input disabled 1 - Schmitt trigger input enabled
  [13:11] PADCONFIG65_DEBOUNCE_SEL rw — Selects the debouce period for the pad.
  [8] PADCONFIG65_WK_LVL_POL rw — Level Sensitive Wakeup PolarityThis bit is not relevant unless wk_lvl_en is set to 1'b1.0 - Low. A low (0) value on the pin causes a wakeup1 - High. A high (1) value on the pin causes a wakeup
  [7] PADCONFIG65_WK_LVL_EN rw — Level Sensitive Wakeup Enable0 - Disabled. Wakeup is triggered by change of the pin input value1 - Enabled. Wakeup is triggered when the pin matches the value specified by wk_lvl_pol. The chosen polarity must be maintained. (e.g. until wakeup completion is confirmed)
  [5:4] PADCONFIG65_VGPIO_SEL rw — Virtual MAIN_GPIO instance select.These bits select which instance of GPIO is used for this I/O pad. This allows protection between two different Processor virtual worlds. These bits have no effect if GPIO mode (muxmode=7) is not selected for the PAD. Field values (Others are reserved): 2'b00 - Implement GPIO in GPIO_WKUP_0 instance 2'b01 - Implement GPIO in GPIO_WKUP_2 instance 2'b10 - Implement GPIO in GPIO_WKUP_4 instance 2'b11 - Implement GPIO in GPIO_WKUP_6 instance
  [3:0] PADCONFIG65_MUXMODE rw — Pad functional signal mux selection Field values (Others are reserved): 4'b0000 - Mux Mode 0 4'b0001 - Mux Mode 1 4'b0010 - Mux Mode 2 4'b0011 - Mux Mode 3 4'b0100 - Mux Mode 4 4'b0101 - Mux Mode 5 4'b0110 - Mux Mode 6 4'b0111 - Mux Mode 7 4'b1000 - Mux Mode 8 4'b1001 - Mux Mode 9 4'b1010 - Mux Mode 10 4'b1011 - Mux Mode 11 4'b1100 - Mux Mode 12 4'b1101 - Mux Mode 13 4'b1110 - Mux Mode 14 4'b1111 - Mux Mode 15
